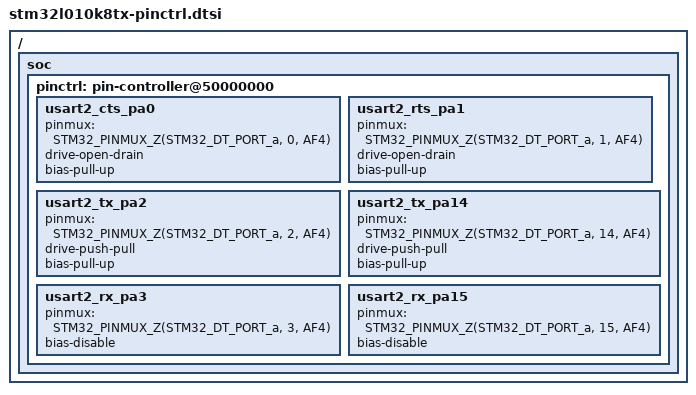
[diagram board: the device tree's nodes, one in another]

/*
 * NOTE: Autogenerated file using stm32_pinctrl_gen.py
 *
 * SPDX-License-Identifier: Apache-2.0
 */

#include <dt-bindings/pinctrl/stm32-pinctrl.h>

/ {
	soc {
		pinctrl: pin-controller@50000000 {
			/* UART_CTS */
			usart2_cts_pa0: usart2_cts_pa0 {
				pinmux = <STM32_PINMUX_Z(STM32_DT_PORT_a, 0, AF4)>;
				drive-open-drain;
				bias-pull-up;
			};


			/* UART_RTS */
			usart2_rts_pa1: usart2_rts_pa1 {
				pinmux = <STM32_PINMUX_Z(STM32_DT_PORT_a, 1, AF4)>;
				drive-open-drain;
				bias-pull-up;
			};


			/* UART_TX */
			usart2_tx_pa2: usart2_tx_pa2 {
				pinmux = <STM32_PINMUX_Z(STM32_DT_PORT_a, 2, AF4)>;
				drive-push-pull;
				bias-pull-up;
			};

			usart2_tx_pa14: usart2_tx_pa14 {
				pinmux = <STM32_PINMUX_Z(STM32_DT_PORT_a, 14, AF4)>;
				drive-push-pull;
				bias-pull-up;
			};


			/* UART_RX */
			usart2_rx_pa3: usart2_rx_pa3 {
				pinmux = <STM32_PINMUX_Z(STM32_DT_PORT_a, 3, AF4)>;
				bias-disable;
			};

			usart2_rx_pa15: usart2_rx_pa15 {
				pinmux = <STM32_PINMUX_Z(STM32_DT_PORT_a, 15, AF4)>;
				bias-disable;
			};

		};
	};
};
